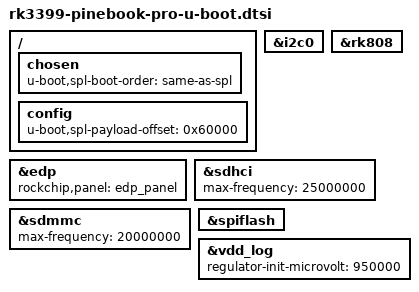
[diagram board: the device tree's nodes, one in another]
// SPDX-License-Identifier: GPL-2.0+
/*
 * Copyright (C) 2019 Peter Robinson <pbrobinson at gmail.com>
 */

#include "rk3399-u-boot.dtsi"
#include "rk3399-sdram-lpddr4-100.dtsi"

/ {
	chosen {
		u-boot,spl-boot-order = "same-as-spl", &sdhci, &spiflash, &sdmmc;
	};

	config {
		u-boot,spl-payload-offset = <0x60000>; /* @ 384KB */
	};
};

&edp {
	rockchip,panel = <&edp_panel>;
};

&i2c0 {
	u-boot,dm-all;
};

&rk808 {
	u-boot,dm-all;
};

&sdhci {
	max-frequency = <25000000>;
	u-boot,dm-all;
};

&sdmmc {
	max-frequency = <20000000>;
	u-boot,dm-all;
};

&spiflash {
	u-boot,dm-all;
};

&vdd_log {
	regulator-init-microvolt = <950000>;
};
